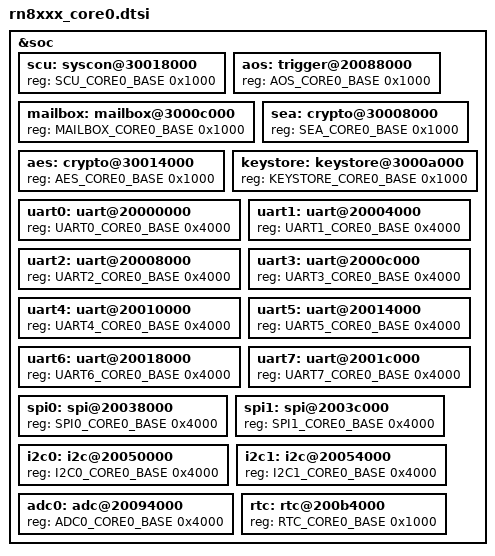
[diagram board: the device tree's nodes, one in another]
/*
 * Copyright (c) 2025 Renergy Technology
 * SPDX-License-Identifier: Apache-2.0
 */

#include <renergy/rn8xxx.dtsi>

&soc {
	/* 覆盖基地址至 Core 0 视图 */
	scu: syscon@30018000 { reg = <SCU_CORE0_BASE 0x1000>; };
	aos: trigger@20088000 { reg = <AOS_CORE0_BASE 0x1000>; };
	mailbox: mailbox@3000c000 { reg = <MAILBOX_CORE0_BASE 0x1000>; };

	sea: crypto@30008000 { reg = <SEA_CORE0_BASE 0x1000>; };
	aes: crypto@30014000 { reg = <AES_CORE0_BASE 0x1000>; };
	keystore: keystore@3000a000 { reg = <KEYSTORE_CORE0_BASE 0x1000>; };

	uart0: uart@20000000 { reg = <UART0_CORE0_BASE 0x4000>; };
	uart1: uart@20004000 { reg = <UART1_CORE0_BASE 0x4000>; };
	uart2: uart@20008000 { reg = <UART2_CORE0_BASE 0x4000>; };
	uart3: uart@2000c000 { reg = <UART3_CORE0_BASE 0x4000>; };
	uart4: uart@20010000 { reg = <UART4_CORE0_BASE 0x4000>; };
	uart5: uart@20014000 { reg = <UART5_CORE0_BASE 0x4000>; };
	uart6: uart@20018000 { reg = <UART6_CORE0_BASE 0x4000>; };
	uart7: uart@2001c000 { reg = <UART7_CORE0_BASE 0x4000>; };

	spi0: spi@20038000 { reg = <SPI0_CORE0_BASE 0x4000>; };
	spi1: spi@2003c000 { reg = <SPI1_CORE0_BASE 0x4000>; };

	i2c0: i2c@20050000 { reg = <I2C0_CORE0_BASE 0x4000>; };
	i2c1: i2c@20054000 { reg = <I2C1_CORE0_BASE 0x4000>; };

	adc0: adc@20094000 { reg = <ADC0_CORE0_BASE 0x4000>; };
	rtc: rtc@200b4000 { reg = <RTC_CORE0_BASE 0x1000>; };
};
